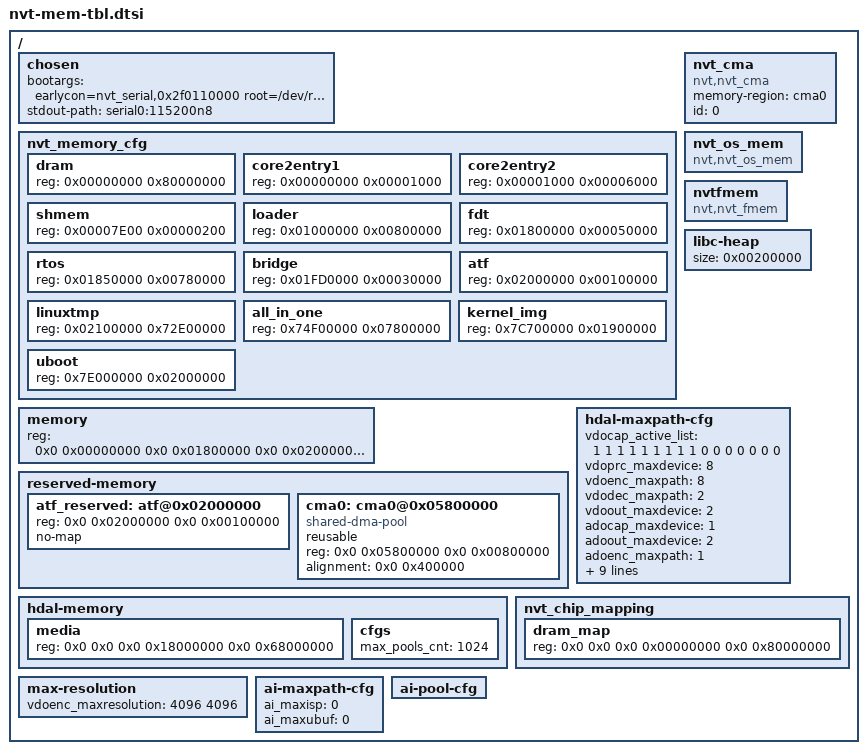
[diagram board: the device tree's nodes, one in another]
/*
 * Novatek Ltd. BSP part of dts
 */
/ {
	chosen {
		bootargs = "earlycon=nvt_serial,0x2f0110000 root=/dev/ram0 rootfstype=ramfs rdinit=/linuxrc ";
		stdout-path = "serial0:115200n8";
	};

	/* Uboot/loader memory layout */
	/* !!! for rtos booting linux !!!
	 * 1. fdt, rtos and bridge memory region must be contiguous.
	 * 2. fdt, rtos and bridge memory region cannot overlap with hdal and linux memory
	 * 3. fdt, rtos and bridge memory region cannot overlap with linuxtmp
	 * 4. fdt, rtos and bridge memory have to start at 8MB alignment, and the size also needs 8MB alignment
	 * 5. uboot memory cannot be overlapped with linux system memory region
	 * 6. for this sample, (fdt+rtos+bridge) located at 24MB(0x01800000), because loader @16MB, loader's tmp(SDRAM_Start_FW) @32MB
	 */
	nvt_memory_cfg {
		#address-cells = <1>;
		#size-cells = <1>;
		dram {          reg = <0x00000000 0x80000000>;};
		core2entry1 {	reg = <0x00000000 0x00001000>;};  /* recycled after aft started */
		core2entry2 {	reg = <0x00001000 0x00006000>;};  /* recycled after aft started */
		shmem {         reg = <0x00007E00 0x00000200>;};  /* recycled after rtos started */
		loader {        reg = <0x01000000 0x00800000>;};  /* recycled after uboot started */
		fdt {           reg = <0x01800000 0x00050000>;};  /* recycled after linux started */
		rtos {          reg = <0x01850000 0x00780000>;};  /* recycled after linux started */
		bridge {        reg = <0x01FD0000 0x00030000>;};  /* recycled after linux started */
		atf {           reg = <0x02000000 0x00100000>;};  /* always exists */
		linuxtmp {      reg = <0x02100000 0x72E00000>; };  /* recycled after rtos started */
		all_in_one {    reg = <0x74F00000 0x07800000>;  };
		kernel_img {    reg = <0x7C700000 0x01900000>;  };
		uboot{          reg = <0x7E000000 0x02000000>;  };
	};
	/* Linux system memory region*/
	memory { device_type = "memory"; reg = <0x0 0x00000000 0x0 0x01800000 0x0 0x02000000 0x0 0x16000000>; };

	/* Linux setup reserved memory */
	reserved-memory {
		#address-cells = <2>;
		#size-cells = <2>;
		ranges;
		atf_reserved: atf@0x02000000 {
			reg = <0x0 0x02000000 0x0 0x00100000>;
			no-map;
		};

		cma0: cma0@0x05800000 {
			compatible = "shared-dma-pool";
			reusable;
			reg = <0x0 0x05800000 0x0 0x00800000>;
			alignment = <0x0 0x400000>;
			status = "okay";
		};
	};

	nvt_cma {
		compatible = "nvt,nvt_cma";
		memory-region = <&cma0>;
		id = <0>;
	};

	nvt_os_mem {
		compatible = "nvt,nvt_os_mem";
	};

	nvtfmem {
		compatible = "nvt,nvt_fmem";
	};

	 /*
	 * rtos libc heap expected minimum size
	 * becasue remain of rtos memory will be the libc heap automatically,
	 * if it too small against your expectation, there will be a assert on boot.
	 */
	libc-heap { size = <0x00200000>; };

	hdal-memory {
		#address-cells = <4>;
		#size-cells = <2>;
		media {
			reg = <
				0x0 0x0 0x0 0x18000000 0x0 0x68000000 /* [DDRID-H][DDRID-L] [ADDR-H][ADDR-L] [SIZE-H][SIZE-L]  */
			>;
		};
		cfgs {
			max_pools_cnt = <1024>;
		};
	};

	hdal-maxpath-cfg {
		/* First is for VCAP0, second for VCAP1 and so on.*/
		vdocap_active_list   = <1 1 1 1 1 1 1 1 1 0 0 0 0 0 0 0>;
		vdoprc_maxdevice   = <8>;
		vdoenc_maxpath     = <8>;
		vdodec_maxpath     = <2>;
		vdoout_maxdevice   = <2>;
		adocap_maxdevice   = <1>;
		adoout_maxdevice   = <2>;
		adoenc_maxpath     = <1>;
		adodec_maxpath     = <1>;
		/* gfx jog list */
		gfx_maxjob = <2>;
		/* stamp max img buffer number */
		stamp_maximg = <64>;
		/* First is internal stamp number, second is external stamp number */
		vdoprc_maxstamp = <0  16>;
		/* First is internal mask number, second is external mask number */
		vdoprc_maxmask   = <8  64>;
		vdoenc_maxstamp  = <32 16>;
		vdoenc_maxmask   = <16 64>;
		vdoout_maxstamp  = <0  16>;
		vdoout_maxmask   = <0  64>;
	};
	/* To config the nvt chip mapping relationship */
	nvt_chip_mapping {
		#address-cells = <4>;
		#size-cells = <2>;
		dram_map {
			reg = <
				0x0 0x0 0x0 0x00000000 0x0 0x80000000		/* [DDRID] [CHIPID] [ADDR-H] [ADDR-L] [SIZE-H] [SIZE-L] */
			>;
		};
	};

	/*
	framebuffer1-1 {
		copy = <1>;
		//[DDRID] [CHIPID] [ADDR-H] [ADDR-L] [SIZE]
		buffer = <0 0 0 0x7F000000 0x01000000>; };
	*/

	max-resolution {
		/* VENC max resolution <width height> */
		vdoenc_maxresolution   = <4096 4096>;
	};
	ai-maxpath-cfg {
		/* max ai-isp effect */
		ai_maxisp = <0>;
		/* max ai-isp required ubuf(0.5MB), must be 0~3 */
		ai_maxubuf = <0>;
	};
	ai-pool-cfg {
		/*
		[UB status]   (1:on, 2:shared)
		[UB st_id]    (UBUF start idex) st_id to end_id must be continuous
		[UB end_id]   (UBUF end idex)
		[Core st_ch]  (Core num start channel) st_ch to end_ch must be continuous
		[Core end_ch] (Core num end channel)
		*/
 		/*
 		pool_0= <1 0 0 0 0> ; //[UB status][UB st_id][UB end_id][Core st_ch][Core end_ch]
		pool_1= <1 0 0 0 0> ; //[UB status][UB st_id][UB end_id][Core st_ch][Core end_ch]
		pool_2= <1 0 0 0 0> ; //[UB status][UB st_id][UB end_id][Core st_ch][Core end_ch]
		pool_3= <1 0 0 0 0> ; //[UB status][UB st_id][UB end_id][Core st_ch][Core end_ch]
		*/
	};

};
